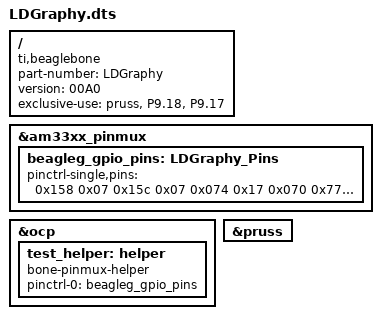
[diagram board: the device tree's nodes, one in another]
/*
 * Based on github.com/jadonk/validation-scripts/tree/master/test-capemgr
 * Copyright (C) 2012 Texas Instruments Incorporated - http://www.ti.com/
 *
 * This program is free software; you can redistribute it and/or modify
 * it under the terms of the GNU General Purpose License Version 2 as
 * published by the Free Software Foundation
 *
 * To create the binary representation that the device manager can handle, run
 *   make LDGraphy-00A0.dtbo
 * (The binary fill is checked into github, so this is only needed if you are
 *  modifying this file)
 */

/dts-v1/;
/plugin/;

/{
    compatible = "ti,beaglebone", "ti,beaglebone-black", "ti,beaglebone-green";
    part-number = "LDGraphy";
    version = "00A0";

    exclusive-use = "pruss",  // Programmable realtime unit
    		  "P9.18", "P9.17";

    fragment@0 {
        target = <&am33xx_pinmux>;
        __overlay__ {
            beagleg_gpio_pins: LDGraphy_Pins {
                pinctrl-single,pins = <
		    /* Pixel data */
		    0x158 0x07 /* GPIO_0[4] ; P9.18 Polygon Mirror Clock */
		    0x15c 0x07 /* GPIO_0[5] ; P9.17 Laser Data */
		    0x074 0x17 /* GPIO_0[31]; P9.13 Motor Enable; pullup */

		    /* Input */
		    /* Not sure if slow slew means what I think it means: assuming that
		       it enables a SchmittTrigger at the GPIO input.
		       (Output of our OpAmp is slow, only 10V/us */
		    0x070 0x77 /* GPIO_0[30]; P9.11 Hsync input. Pullup. Slow Slew */

		    0x044 0x07 /* GPIO_1[17]; P9.23 Mirror + Stepper Enable */

		    /* Sled stepper */
		    0x040 0x07 /* GPIO_1[16]; P9.15 Dir */
		    0x048 0x07 /* GPIO_1[18]; P9.14 Step */
                >;
            };
        };
    };

    fragment@1 {
        target = <&ocp>;
        __overlay__ {
            test_helper: helper {
                compatible = "bone-pinmux-helper";
                pinctrl-names = "default";
                pinctrl-0 = <&beagleg_gpio_pins>;
                status = "okay";
            };
        };
    };

   fragment@2{
        target = <&pruss>;
        __overlay__ {
            status = "okay";
        };
   };
};
